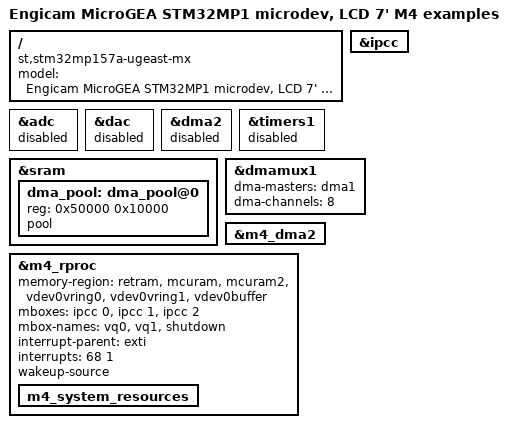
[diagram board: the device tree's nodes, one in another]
// SPDX-License-Identifier: (GPL-2.0+ OR BSD-3-Clause)
/*
 * Copyright (C) STMicroelectronics 2017 - All Rights Reserved
 * Author: Alexandre Torgue <alexandre.torgue@st.com> for STMicroelectronics.
 */

/dts-v1/;

#include "stm32mp157a-ugeast-mx-lcd7.dts"

/ {
		model = "Engicam MicroGEA STM32MP1 microdev, LCD 7' M4 examples";
		compatible = "st,stm32mp157a-ugeast-mx", "st,stm32mp157";
};

&adc {
	status = "disabled";
};

&dac {
	status = "disabled";
};

&dma2 {
	status = "disabled";
};

&timers1 {
	status = "disabled";
};

&ipcc {
	status = "okay";
};

&sram {
	dma_pool: dma_pool@0 {
		reg = <0x50000 0x10000>;
		pool;
	};
};

&dmamux1 {
	dma-masters = <&dma1>;
	dma-channels = <8>;
};

&m4_dma2 {
	status = "okay";
};

&m4_rproc {	
	memory-region = <&retram>, <&mcuram>, <&mcuram2>, <&vdev0vring0>,
			<&vdev0vring1>, <&vdev0buffer>;
	mboxes = <&ipcc 0>, <&ipcc 1>, <&ipcc 2>;
	mbox-names = "vq0", "vq1", "shutdown";
	interrupt-parent = <&exti>;
	interrupts = <68 1>;
	wakeup-source;
	status = "okay";
	
	m4_system_resources {
		status = "okay";
	};
};
  
/* USER CODE END addons */

 
/*
&dmamux1 {
	dma-masters = <&dma1>;
	dma-channels = <8>;
};

&m4_dma2 {
	status = "okay";
};

&m4_crc2 {
	status = "okay";
};

&m4_cryp2 {
	status = "okay";
};

&m4_hash2 {
	status = "okay";
};

&m4_rng2 {
	status = "okay";
};

&m4_rproc{

	status = "okay";
		m4_system_resources{
		status = "okay";
		};
};*/

